AUTOSAR XML (schema 4-2-2)
package /ComponentTypes
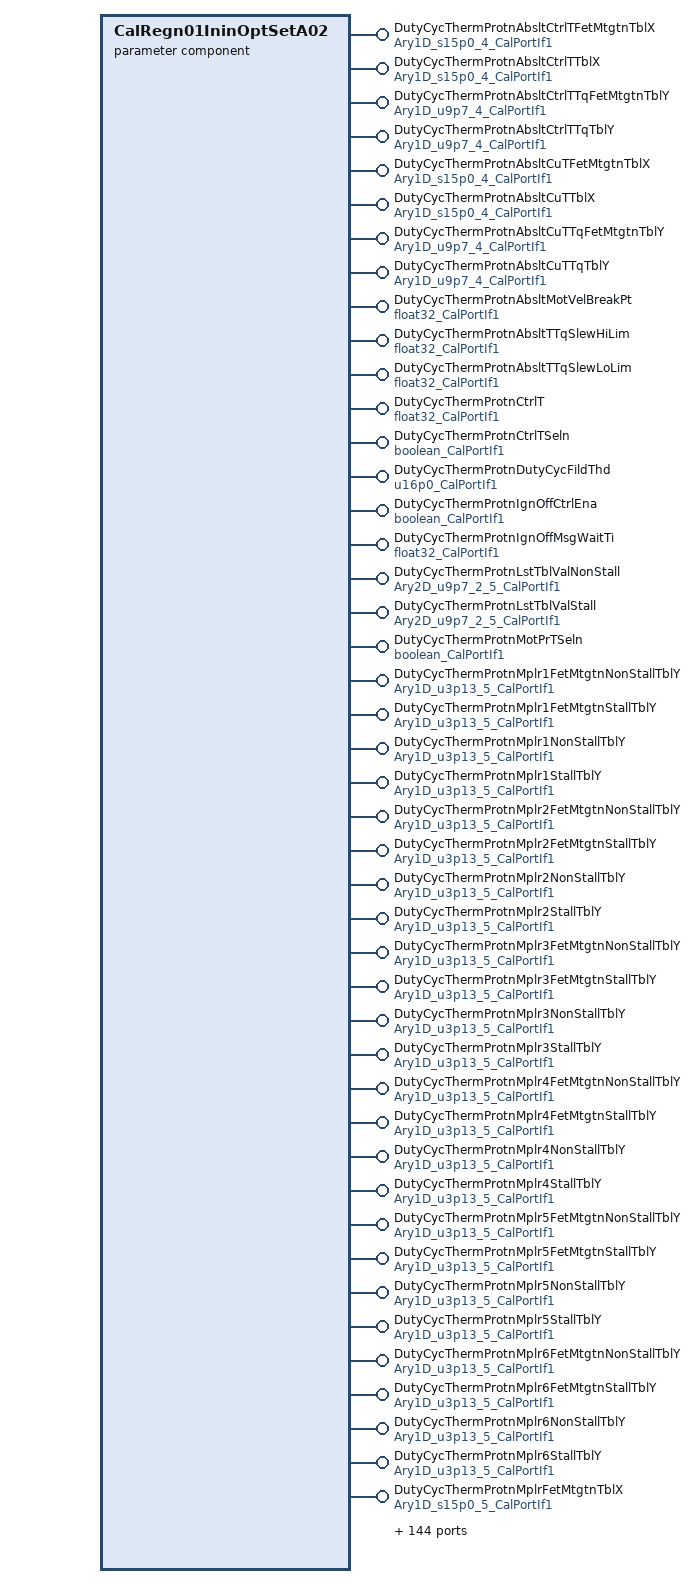
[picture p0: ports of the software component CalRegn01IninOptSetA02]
  parameter sw component type CalRegn01IninOptSetA02
    188 x provide port:
      DutyCycThermProtnAbsltCtrlTFetMtgtnTblX: parameter-provide-com-spec{init-value=[122, 123, 125, 127], parameter=Ary1D}, provided-interface=Ary1D_s15p0_4_CalPortIf1
      DutyCycThermProtnAbsltCtrlTTblX: parameter-provide-com-spec{init-value=[122, 123, 125, 127], parameter=Ary1D}, provided-interface=Ary1D_s15p0_4_CalPortIf1
      DutyCycThermProtnAbsltCtrlTTqFetMtgtnTblY: parameter-provide-com-spec{init-value=[346, 287, 234, 0], parameter=Ary1D}, provided-interface=Ary1D_u9p7_4_CalPortIf1
      DutyCycThermProtnAbsltCtrlTTqTblY: parameter-provide-com-spec{init-value=[346, 287, 234, 0], parameter=Ary1D}, provided-interface=Ary1D_u9p7_4_CalPortIf1
      DutyCycThermProtnAbsltCuTFetMtgtnTblX: parameter-provide-com-spec{init-value=[122, 123, 125, 127], parameter=Ary1D}, provided-interface=Ary1D_s15p0_4_CalPortIf1
      DutyCycThermProtnAbsltCuTTblX: parameter-provide-com-spec{init-value=[122, 123, 125, 127], parameter=Ary1D}, provided-interface=Ary1D_s15p0_4_CalPortIf1
      DutyCycThermProtnAbsltCuTTqFetMtgtnTblY: parameter-provide-com-spec{init-value=[346, 287, 234, 0], parameter=Ary1D}, provided-interface=Ary1D_u9p7_4_CalPortIf1
      DutyCycThermProtnAbsltCuTTqTblY: parameter-provide-com-spec{init-value=[346, 287, 234, 0], parameter=Ary1D}, provided-interface=Ary1D_u9p7_4_CalPortIf1
      DutyCycThermProtnAbsltMotVelBreakPt: parameter-provide-com-spec{init-value=1.375, parameter=Val}, provided-interface=float32_CalPortIf1
      DutyCycThermProtnAbsltTTqSlewHiLim: parameter-provide-com-spec{init-value=0.3, parameter=Val}, provided-interface=float32_CalPortIf1
      DutyCycThermProtnAbsltTTqSlewLoLim: parameter-provide-com-spec{init-value=0.3, parameter=Val}, provided-interface=float32_CalPortIf1
      DutyCycThermProtnCtrlT: parameter-provide-com-spec{init-value=70, parameter=Val}, provided-interface=float32_CalPortIf1
      DutyCycThermProtnCtrlTSeln: parameter-provide-com-spec{init-value=1, parameter=Logl}, provided-interface=boolean_CalPortIf1
      DutyCycThermProtnDutyCycFildThd: parameter-provide-com-spec{init-value=92, parameter=Val}, provided-interface=u16p0_CalPortIf1
      DutyCycThermProtnIgnOffCtrlEna: parameter-provide-com-spec{init-value=0, parameter=Logl}, provided-interface=boolean_CalPortIf1
      DutyCycThermProtnIgnOffMsgWaitTi: parameter-provide-com-spec{init-value=0.5, parameter=Val}, provided-interface=float32_CalPortIf1
      DutyCycThermProtnLstTblValNonStall: parameter-provide-com-spec{init-value=[[128, 128, 128, 44, 44], [128, 128, 128, 44, 44]], parameter=Ary2D}, provided-interface=Ary2D_u9p7_2_5_CalPortIf1
      DutyCycThermProtnLstTblValStall: parameter-provide-com-spec{init-value=[[124, 124, 124, 40, 40], [124, 124, 124, 40, 40]], parameter=Ary2D}, provided-interface=Ary2D_u9p7_2_5_CalPortIf1
      DutyCycThermProtnMotPrTSeln: parameter-provide-com-spec{init-value=1, parameter=Logl}, provided-interface=boolean_CalPortIf1
      DutyCycThermProtnMplr1FetMtgtnNonStallTblY: parameter-provide-com-spec{init-value=[127, 127, 127, 1630, 1630], parameter=Ary1D}, provided-interface=Ary1D_u3p13_5_CalPortIf1
      DutyCycThermProtnMplr1FetMtgtnStallTblY: parameter-provide-com-spec{init-value=[133, 133, 133, 180, 180], parameter=Ary1D}, provided-interface=Ary1D_u3p13_5_CalPortIf1
      DutyCycThermProtnMplr1NonStallTblY: parameter-provide-com-spec{init-value=[127, 127, 127, 1630, 1630], parameter=Ary1D}, provided-interface=Ary1D_u3p13_5_CalPortIf1
      DutyCycThermProtnMplr1StallTblY: parameter-provide-com-spec{init-value=[133, 133, 133, 180, 180], parameter=Ary1D}, provided-interface=Ary1D_u3p13_5_CalPortIf1
      DutyCycThermProtnMplr2FetMtgtnNonStallTblY: parameter-provide-com-spec{init-value=[159, 159, 159, 281, 281], parameter=Ary1D}, provided-interface=Ary1D_u3p13_5_CalPortIf1
      DutyCycThermProtnMplr2FetMtgtnStallTblY: parameter-provide-com-spec{init-value=[167, 167, 167, 310, 310], parameter=Ary1D}, provided-interface=Ary1D_u3p13_5_CalPortIf1
      DutyCycThermProtnMplr2NonStallTblY: parameter-provide-com-spec{init-value=[159, 159, 159, 281, 281], parameter=Ary1D}, provided-interface=Ary1D_u3p13_5_CalPortIf1
      DutyCycThermProtnMplr2StallTblY: parameter-provide-com-spec{init-value=[167, 167, 167, 310, 310], parameter=Ary1D}, provided-interface=Ary1D_u3p13_5_CalPortIf1
      DutyCycThermProtnMplr3FetMtgtnNonStallTblY: parameter-provide-com-spec{init-value=[199, 199, 199, 1282, 1282], parameter=Ary1D}, provided-interface=Ary1D_u3p13_5_CalPortIf1
      DutyCycThermProtnMplr3FetMtgtnStallTblY: parameter-provide-com-spec{init-value=[210, 210, 210, 1707, 1707], parameter=Ary1D}, provided-interface=Ary1D_u3p13_5_CalPortIf1
      DutyCycThermProtnMplr3NonStallTblY: parameter-provide-com-spec{init-value=[199, 199, 199, 1282, 1282], parameter=Ary1D}, provided-interface=Ary1D_u3p13_5_CalPortIf1
      DutyCycThermProtnMplr3StallTblY: parameter-provide-com-spec{init-value=[210, 210, 210, 1707, 1707], parameter=Ary1D}, provided-interface=Ary1D_u3p13_5_CalPortIf1
      DutyCycThermProtnMplr4FetMtgtnNonStallTblY: parameter-provide-com-spec{init-value=5 x 1, parameter=Ary1D}, provided-interface=Ary1D_u3p13_5_CalPortIf1
      DutyCycThermProtnMplr4FetMtgtnStallTblY: parameter-provide-com-spec{init-value=5 x 1, parameter=Ary1D}, provided-interface=Ary1D_u3p13_5_CalPortIf1
      DutyCycThermProtnMplr4NonStallTblY: parameter-provide-com-spec{init-value=5 x 1, parameter=Ary1D}, provided-interface=Ary1D_u3p13_5_CalPortIf1
      DutyCycThermProtnMplr4StallTblY: parameter-provide-com-spec{init-value=5 x 1, parameter=Ary1D}, provided-interface=Ary1D_u3p13_5_CalPortIf1
      DutyCycThermProtnMplr5FetMtgtnNonStallTblY: parameter-provide-com-spec{init-value=[998, 998, 998, 9535, 9535], parameter=Ary1D}, provided-interface=Ary1D_u3p13_5_CalPortIf1
      DutyCycThermProtnMplr5FetMtgtnStallTblY: parameter-provide-com-spec{init-value=[998, 998, 998, 9535, 9535], parameter=Ary1D}, provided-interface=Ary1D_u3p13_5_CalPortIf1
      DutyCycThermProtnMplr5NonStallTblY: parameter-provide-com-spec{init-value=[998, 998, 998, 9535, 9535], parameter=Ary1D}, provided-interface=Ary1D_u3p13_5_CalPortIf1
      DutyCycThermProtnMplr5StallTblY: parameter-provide-com-spec{init-value=[998, 998, 998, 9535, 9535], parameter=Ary1D}, provided-interface=Ary1D_u3p13_5_CalPortIf1
      DutyCycThermProtnMplr6FetMtgtnNonStallTblY: parameter-provide-com-spec{init-value=5 x 1, parameter=Ary1D}, provided-interface=Ary1D_u3p13_5_CalPortIf1
      DutyCycThermProtnMplr6FetMtgtnStallTblY: parameter-provide-com-spec{init-value=5 x 1, parameter=Ary1D}, provided-interface=Ary1D_u3p13_5_CalPortIf1
      DutyCycThermProtnMplr6NonStallTblY: parameter-provide-com-spec{init-value=5 x 1, parameter=Ary1D}, provided-interface=Ary1D_u3p13_5_CalPortIf1
      DutyCycThermProtnMplr6StallTblY: parameter-provide-com-spec{init-value=5 x 1, parameter=Ary1D}, provided-interface=Ary1D_u3p13_5_CalPortIf1
      DutyCycThermProtnMplrFetMtgtnTblX: parameter-provide-com-spec{init-value=[-40, 0, 83, 84, 85], parameter=Ary1D}, provided-interface=Ary1D_s15p0_5_CalPortIf1
      DutyCycThermProtnMplrTblX: parameter-provide-com-spec{init-value=[-40, 0, 83, 84, 85], parameter=Ary1D}, provided-interface=Ary1D_s15p0_5_CalPortIf1
      DutyCycThermProtnMplrTSeln: parameter-provide-com-spec{init-value=1, parameter=Logl}, provided-interface=boolean_CalPortIf1
      DutyCycThermProtnSlowFilTSeln: parameter-provide-com-spec{init-value=0, parameter=Logl}, provided-interface=boolean_CalPortIf1
      DutyCycThermProtnThermLimScaFac: parameter-provide-com-spec{init-value=0.5, parameter=Val}, provided-interface=float32_CalPortIf1
      DutyCycThermProtnThermLoadLimTblX: parameter-provide-com-spec{init-value=[[0, 76, 80, 84, 88, 92, 96, 100], [0, 76, 80, 84, 88, 92, 96, 100]], parameter=Ary2D}, provided-interface=Ary2D_u16p0_2_8_CalPortIf1
      DutyCycThermProtnThermLoadLimTblY: parameter-provide-com-spec{init-value=[[346, 346, 346, 346, 287, 234, 181, 128], [346, 346, 346, 346, 287, 234, 181, 128]], parameter=Ary2D}, provided-interface=Ary2D_u9p7_2_8_CalPortIf1
      DutyCycThermProtnTqCmdSlewDwn: parameter-provide-com-spec{init-value=0.3, parameter=Val}, provided-interface=float32_CalPortIf1
      DutyCycThermProtnTqCmdSlewUp: parameter-provide-com-spec{init-value=0.3, parameter=Val}, provided-interface=float32_CalPortIf1
      HiLoadStallLimrMotVelMgnThd: parameter-provide-com-spec{init-value=[1.375, 1.375], parameter=Ary1D}, provided-interface=Ary1D_f32_2_CalPortIf1
      HiLoadStallLimrStallMotTqCmdFetMtgtnLimX: parameter-provide-com-spec{init-value=[0, 563, 640, 717, 768, 768], parameter=Ary1D}, provided-interface=Ary1D_u8p8_6_CalPortIf1
      HiLoadStallLimrStallMotTqCmdFetMtgtnLimY: parameter-provide-com-spec{init-value=[768, 768, 512, 256, 0, 0], parameter=Ary1D}, provided-interface=Ary1D_u8p8_6_CalPortIf1
      HiLoadStallLimrStallMotTqCmdLimX: parameter-provide-com-spec{init-value=[0, 563, 640, 717, 768, 768], parameter=Ary1D}, provided-interface=Ary1D_u8p8_6_CalPortIf1
      HiLoadStallLimrStallMotTqCmdLimY: parameter-provide-com-spec{init-value=[768, 768, 512, 256, 0, 0], parameter=Ary1D}, provided-interface=Ary1D_u8p8_6_CalPortIf1
      HiLoadStallLimrStallMotTqLimSlewRate: parameter-provide-com-spec{init-value=[0.101563, 0.101563], parameter=Ary1D}, provided-interface=Ary1D_f32_2_CalPortIf1
      HiLoadStallLimrStallThermLimSca: parameter-provide-com-spec{init-value=0.5, parameter=Val}, provided-interface=float32_CalPortIf1
      LrndRackCentrMotTqThd: parameter-provide-com-spec{init-value=2.8, parameter=Val}, provided-interface=float32_CalPortIf1
      LrndRackCentrMotVelThd: parameter-provide-com-spec{init-value=25, parameter=Val}, provided-interface=float32_CalPortIf1
      MotCtrlPrmEstimnFetRNom: parameter-provide-com-spec{init-value=0.0052, parameter=Val}, provided-interface=float32_CalPortIf1
      MotCtrlPrmEstimnMotBackEmfConHiLim: parameter-provide-com-spec{init-value=0.045, parameter=Val}, provided-interface=float32_CalPortIf1
      MotCtrlPrmEstimnMotBackEmfConLoLim: parameter-provide-com-spec{init-value=0.031, parameter=Val}, provided-interface=float32_CalPortIf1
      MotCtrlPrmEstimnMotBackEmfConNom: parameter-provide-com-spec{init-value=0.04, parameter=Val}, provided-interface=float32_CalPortIf1
      MotCtrlPrmEstimnMotBackEmfConSatnScaIvtrLoaMtgtn: parameter-provide-com-spec{init-value=1, parameter=Val}, provided-interface=float32_CalPortIf1
      MotCtrlPrmEstimnMotBackEmfConSatnX: parameter-provide-com-spec{init-value=[0, 1280, 2560, 3840, 5120, 6400, 7680, 8960, 10240, 11520, 12800, 14080, 15360, 16640, 19200, 21760], parameter=Ary1D}, provided-interface=Ary1D_u9p7_16_CalPortIf1
      MotCtrlPrmEstimnMotBackEmfConSatnY: parameter-provide-com-spec{init-value=[16384, 16384, 16384, 16384, 16384, 16384, 16384, 16384, 16384, 16384, 16384, 16370, 16336, 16276, 16095, 15869], parameter=Ary1D}, provided-interface=Ary1D_u2p14_16_CalPortIf1
      MotCtrlPrmEstimnMotCurrDaxInduSatnBilnrSeln: parameter-provide-com-spec{init-value=[0, 3200, 6400, 9600, 12800, 16000], parameter=Ary1D}, provided-interface=Ary1D_u9p7_6_CalPortIf1
      MotCtrlPrmEstimnMotCurrQaxInduSatnX: parameter-provide-com-spec{init-value=[0, 3200, 6400, 9600, 12800, 16000, 19200], parameter=Ary1D}, provided-interface=Ary1D_u9p7_7_CalPortIf1
      MotCtrlPrmEstimnMotInduDaxHiLim: parameter-provide-com-spec{init-value=0.00013, parameter=Val}, provided-interface=float32_CalPortIf1
      MotCtrlPrmEstimnMotInduDaxIvtrLoaMtgtn: parameter-provide-com-spec{init-value=0.00013, parameter=Val}, provided-interface=float32_CalPortIf1
      MotCtrlPrmEstimnMotInduDaxLoLim: parameter-provide-com-spec{init-value=0.0001, parameter=Val}, provided-interface=float32_CalPortIf1
      MotCtrlPrmEstimnMotInduDaxNom: parameter-provide-com-spec{init-value=0.00011889, parameter=Val}, provided-interface=float32_CalPortIf1
      MotCtrlPrmEstimnMotInduDaxSatnScaY: parameter-provide-com-spec{init-value=6 x [16384, 16384, 16384, 16384, 16384, 16305, 16096], parameter=Ary2D}, provided-interface=Ary2D_u2p14_6_7_CalPortIf1
      MotCtrlPrmEstimnMotInduQaxHiLim: parameter-provide-com-spec{init-value=0.00013, parameter=Val}, provided-interface=float32_CalPortIf1
      MotCtrlPrmEstimnMotInduQaxIvtrLoaMtgtn: parameter-provide-com-spec{init-value=0.00013, parameter=Val}, provided-interface=float32_CalPortIf1
      MotCtrlPrmEstimnMotInduQaxLoLim: parameter-provide-com-spec{init-value=0.0001, parameter=Val}, provided-interface=float32_CalPortIf1
      MotCtrlPrmEstimnMotInduQaxNom: parameter-provide-com-spec{init-value=0.00011889, parameter=Val}, provided-interface=float32_CalPortIf1
      MotCtrlPrmEstimnMotInduQaxSatnScaY: parameter-provide-com-spec{init-value=6 x [16384, 16384, 16384, 16384, 16384, 16305, 16096], parameter=Ary2D}, provided-interface=Ary2D_u2p14_6_7_CalPortIf1
      MotCtrlPrmEstimnMotRHiLim: parameter-provide-com-spec{init-value=0.032, parameter=Val}, provided-interface=float32_CalPortIf1
      MotCtrlPrmEstimnMotRLoLim: parameter-provide-com-spec{init-value=0.01246, parameter=Val}, provided-interface=float32_CalPortIf1
      MotCtrlPrmEstimnMotRNom: parameter-provide-com-spec{init-value=0.0139, parameter=Val}, provided-interface=float32_CalPortIf1
      MotCtrlPrmEstimnMotWidgThermCoeff: parameter-provide-com-spec{init-value=0.0039, parameter=Val}, provided-interface=float32_CalPortIf1
      MotCtrlPrmEstimnTNom: parameter-provide-com-spec{init-value=25, parameter=Val}, provided-interface=float32_CalPortIf1
      MotCurrPeakEstimnCurrFilFrq: parameter-provide-com-spec{init-value=8, parameter=Val}, provided-interface=float32_CalPortIf1
      MotCurrPeakEstimnCurrPeakEstimdFilFrq: parameter-provide-com-spec{init-value=0.03, parameter=Val}, provided-interface=float32_CalPortIf1
      MotCurrRegCfgMotClsdLoopBwDaxY: parameter-provide-com-spec{init-value=[12800, 19200, 19200, 19200], parameter=Ary1D}, provided-interface=Ary1D_u10p6_4_CalPortIf1
      MotCurrRegCfgMotClsdLoopBwQaxY: parameter-provide-com-spec{init-value=[12800, 19200, 19200, 19200], parameter=Ary1D}, provided-interface=Ary1D_u10p6_4_CalPortIf1
      MotCurrRegCfgMotDampgRatDax: parameter-provide-com-spec{init-value=1, parameter=Val}, provided-interface=float32_CalPortIf1
      MotCurrRegCfgMotDampgRatQax: parameter-provide-com-spec{init-value=1, parameter=Val}, provided-interface=float32_CalPortIf1
      MotCurrRegCfgMotNatFrqDaxY: parameter-provide-com-spec{init-value=[38400, 38400, 38400, 38400], parameter=Ary1D}, provided-interface=Ary1D_u9p7_4_CalPortIf1
      MotCurrRegCfgMotNatFrqQaxY: parameter-provide-com-spec{init-value=[38400, 38400, 38400, 38400], parameter=Ary1D}, provided-interface=Ary1D_u9p7_4_CalPortIf1
      MotCurrRegCfgMotRVirtDax: parameter-provide-com-spec{init-value=0, parameter=Val}, provided-interface=float32_CalPortIf1
      MotCurrRegCfgMotRVirtQax: parameter-provide-com-spec{init-value=0, parameter=Val}, provided-interface=float32_CalPortIf1
      MotCurrRegCfgMotVelFilFrq: parameter-provide-com-spec{init-value=10, parameter=Val}, provided-interface=float32_CalPortIf1
      MotCurrRegVltgLimrCurrLoaScarSlewRate: parameter-provide-com-spec{init-value=100, parameter=Val}, provided-interface=float32_CalPortIf1
      MotCurrRegVltgLimrDaxAntiWdupCoeff: parameter-provide-com-spec{init-value=0, parameter=Val}, provided-interface=float32_CalPortIf1
      MotCurrRegVltgLimrDualEcuLoaScarSlewRate: parameter-provide-com-spec{init-value=100, parameter=Val}, provided-interface=float32_CalPortIf1
      MotCurrRegVltgLimrFETLoaScarSlewRate: parameter-provide-com-spec{init-value=100, parameter=Val}, provided-interface=float32_CalPortIf1
      MotCurrRegVltgLimrIvtrLoaScarSlewRate: parameter-provide-com-spec{init-value=100, parameter=Val}, provided-interface=float32_CalPortIf1
      MotCurrRegVltgLimrMotVltgBrdgLpFilFrq: parameter-provide-com-spec{init-value=200, parameter=Val}, provided-interface=float32_CalPortIf1
      MotCurrRegVltgLimrMotVltgDaxIntglHiLim: parameter-provide-com-spec{init-value=9, parameter=Val}, provided-interface=float32_CalPortIf1
      MotCurrRegVltgLimrMotVltgDaxIntglLoLim: parameter-provide-com-spec{init-value=-4.5, parameter=Val}, provided-interface=float32_CalPortIf1
      MotCurrRegVltgLimrMotVltgQaxFfLpFilFrq: parameter-provide-com-spec{init-value=500, parameter=Val}, provided-interface=float32_CalPortIf1
      MotCurrRegVltgLimrMotVltgQaxIntglHiLim: parameter-provide-com-spec{init-value=14.5, parameter=Val}, provided-interface=float32_CalPortIf1
      MotCurrRegVltgLimrMotVltgQaxIntglLoLim: parameter-provide-com-spec{init-value=-14.5, parameter=Val}, provided-interface=float32_CalPortIf1
      MotCurrRegVltgLimrQaxAntiWdupCoeff: parameter-provide-com-spec{init-value=0, parameter=Val}, provided-interface=float32_CalPortIf1
      MotCurrRegVltgLimrQaxAntiWdupScagDi: parameter-provide-com-spec{init-value=0, parameter=Logl}, provided-interface=boolean_CalPortIf1
      MotRefMdlCurrDaxBoostGain: parameter-provide-com-spec{init-value=0, parameter=Val}, provided-interface=float32_CalPortIf1
      MotRefMdlCurrDaxBoostTqScaX: parameter-provide-com-spec{init-value=[0, 6144, 7168, 8192, 9216, 10240, 12288, 14336, 16384, 18432, 20480], parameter=Ary1D}, provided-interface=Ary1D_u4p12_11_CalPortIf1
      MotRefMdlCurrDaxBoostTqScaY: parameter-provide-com-spec{init-value=[0, 16384, 19661, 22938, 23757, 25395, 27034, 27853, 29491, 31130, 32768], parameter=Ary1D}, provided-interface=Ary1D_u1p15_11_CalPortIf1
      MotRefMdlCurrDaxQaxRefDelta: parameter-provide-com-spec{init-value=[-3.1415927, -2.3561945, -1.5707964, -0.7853982, 0, 0.7853982, 1.5707964, 2.3561945], parameter=Ary1D}, provided-interface=Ary1D_f32_8_CalPortIf1
      MotRefMdlCurrItrnTolr: parameter-provide-com-spec{init-value=0.1, parameter=Val}, provided-interface=float32_CalPortIf1
      MotRefMdlMotCurrDaxMaxSca: parameter-provide-com-spec{init-value=1, parameter=Val}, provided-interface=float32_CalPortIf1
      MotRefMdlQuad13VltgSdlX: parameter-provide-com-spec{init-value=[0, 3200, 6400, 9600, 16000, 19200, 22400, 25600, 28800, 35200], parameter=Ary1D}, provided-interface=Ary1D_u11p5_10_CalPortIf1
      MotRefMdlQuad13VltgSdlY: parameter-provide-com-spec{init-value=10 x 0, parameter=Ary1D}, provided-interface=Ary1D_u3p13_10_CalPortIf1
      MotRefMdlQuad24VltgSdlX: parameter-provide-com-spec{init-value=[0, 3200, 6400, 9600, 16000, 19200, 22400, 25600, 28800, 35200], parameter=Ary1D}, provided-interface=Ary1D_u11p5_10_CalPortIf1
      MotRefMdlQuad24VltgSdlY: parameter-provide-com-spec{init-value=10 x 0, parameter=Ary1D}, provided-interface=Ary1D_u3p13_10_CalPortIf1
      MotRefMdlVltgOverRThdSca: parameter-provide-com-spec{init-value=0.25, parameter=Val}, provided-interface=float32_CalPortIf1
      MotTqTranlDampgCmdLim: parameter-provide-com-spec{init-value=3, parameter=Val}, provided-interface=float32_CalPortIf1
      MotTqTranlDampgVelThd: parameter-provide-com-spec{init-value=2.3, parameter=Val}, provided-interface=float32_CalPortIf1
      PwrLimrAssiRednLpFilFrq: parameter-provide-com-spec{init-value=0.365, parameter=Val}, provided-interface=float32_CalPortIf1
      PwrLimrBackEmfConStdT: parameter-provide-com-spec{init-value=0.0335999, parameter=Val}, provided-interface=float32_CalPortIf1
      PwrLimrBrdgVltgAdjSlew: parameter-provide-com-spec{init-value=0.5, parameter=Val}, provided-interface=float32_CalPortIf1
      PwrLimrBrdgVltgAltFltAdj: parameter-provide-com-spec{init-value=1, parameter=Val}, provided-interface=float32_CalPortIf1
      PwrLimrFilAssiRednThd: parameter-provide-com-spec{init-value=0.6, parameter=Val}, provided-interface=float32_CalPortIf1
      PwrLimrLoVoltAssiRcvrThd: parameter-provide-com-spec{init-value=13.5, parameter=Val}, provided-interface=float32_CalPortIf1
      PwrLimrLoVoltAssiRcvrTi: parameter-provide-com-spec{init-value=2000, parameter=Val}, provided-interface=uint16_CalPortIf1
      PwrLimrMotEnvlpX: parameter-provide-com-spec{init-value=[-17600, -12800, -10400, -8800, -5657, -4600, -3499, -1731, 0, 1731, 3499, 4600, 5657, 8800], parameter=Ary1D}, provided-interface=Ary1D_s11p4_14_CalPortIf1
      PwrLimrMotEnvlpY: parameter-provide-com-spec{init-value=[1475, 2867, 3891, 4710, 7168, 8397, 9486, 9486, 9486, 9486, 7277, 5994, 4506, 0], parameter=Ary1D}, provided-interface=Ary1D_u5p11_14_CalPortIf1
      PwrLimrMotVelLpFilFrq: parameter-provide-com-spec{init-value=100, parameter=Val}, provided-interface=float32_CalPortIf1
      PwrLimrSpdAdjSlewDec: parameter-provide-com-spec{init-value=3.125, parameter=Val}, provided-interface=float32_CalPortIf1
      PwrLimrSpdAdjSlewEna: parameter-provide-com-spec{init-value=1, parameter=Logl}, provided-interface=boolean_CalPortIf1
      PwrLimrSpdAdjSlewInc: parameter-provide-com-spec{init-value=3125, parameter=Val}, provided-interface=float32_CalPortIf1
      PwrLimrStdOperMotEnvlpX: parameter-provide-com-spec{init-value=[0, 2182, 5717, 7919, 10034, 16320], parameter=Ary1D}, provided-interface=Ary1D_u11p5_6_CalPortIf1
      PwrLimrStdOperMotEnvlpY: parameter-provide-com-spec{init-value=[18973, 18973, 14553, 11989, 9011, 0], parameter=Ary1D}, provided-interface=Ary1D_u4p12_6_CalPortIf1
      PwrLimrVltgDptMotVelOffsX: parameter-provide-com-spec{init-value=[17496, 18728, 18928, 19136, 19336, 19544, 20568, 21592, 22208, 25280], parameter=Ary1D}, provided-interface=Ary1D_u5p11_10_CalPortIf1
      PwrLimrVltgDptMotVelOffsY: parameter-provide-com-spec{init-value=[3395, 2859, 2769, 2680, 2591, 2501, 2054, 1608, 1340, 0], parameter=Ary1D}, provided-interface=Ary1D_u11p5_10_CalPortIf1
      SysGlbPrmSysTqRat: parameter-provide-com-spec{init-value=20, parameter=Val}, provided-interface=float32_CalPortIf1
      TEstimnAmbPwrMplr: parameter-provide-com-spec{init-value=[0.01, 0.01, 0.01], parameter=Ary1D}, provided-interface=Ary1D_f32_3_CalPortIf1
      TEstimnAmbTSca: parameter-provide-com-spec{init-value=[0.9, 0.9, 0.9], parameter=Ary1D}, provided-interface=Ary1D_f32_3_CalPortIf1
      TEstimnAssiMechAmbLpFilFrq: parameter-provide-com-spec{init-value=0.024, parameter=Val}, provided-interface=float32_CalPortIf1
      TEstimnAssiMechAmbLpFilFrqDualEcuFltMtgtn: parameter-provide-com-spec{init-value=0.024, parameter=Val}, provided-interface=float32_CalPortIf1
      TEstimnAssiMechAmbLpFilFrqFetMtgtnEna: parameter-provide-com-spec{init-value=0.024, parameter=Val}, provided-interface=float32_CalPortIf1
      TEstimnAssiMechAmbMplr: parameter-provide-com-spec{init-value=[0.01, 0.01, 0.01], parameter=Ary1D}, provided-interface=Ary1D_f32_3_CalPortIf1
      TEstimnAssiMechCorrLim: parameter-provide-com-spec{init-value=[60, 60, 60], parameter=Ary1D}, provided-interface=Ary1D_f32_3_CalPortIf1
      TEstimnAssiMechDampgSca: parameter-provide-com-spec{init-value=[0.0001, 0.0001, 0.0001], parameter=Ary1D}, provided-interface=Ary1D_f32_3_CalPortIf1
      TEstimnAssiMechDftT: parameter-provide-com-spec{init-value=[50, 50, 50], parameter=Ary1D}, provided-interface=Ary1D_f32_3_CalPortIf1
      TEstimnAssiMechLLFilCoeffA1: parameter-provide-com-spec{init-value=[0.99996858, 0.99996858, 0.99996858], parameter=Ary1D}, provided-interface=Ary1D_f32_3_CalPortIf1
      TEstimnAssiMechLLFilCoeffB0: parameter-provide-com-spec{init-value=[0.4761987, 0.4761987, 0.4761987], parameter=Ary1D}, provided-interface=Ary1D_f32_3_CalPortIf1
      TEstimnAssiMechLLFilCoeffB1: parameter-provide-com-spec{init-value=[-0.4761673, -0.4761673, -0.4761673], parameter=Ary1D}, provided-interface=Ary1D_f32_3_CalPortIf1
      TEstimnAssiMechSlew: parameter-provide-com-spec{init-value=[1, 1, 1], parameter=Ary1D}, provided-interface=Ary1D_f32_3_CalPortIf1
      TEstimnCorrnTAssiMech: parameter-provide-com-spec{init-value=[0, 0, 0], parameter=Ary1D}, provided-interface=Ary1D_f32_3_CalPortIf1
      TEstimnCorrnTCu: parameter-provide-com-spec{init-value=[0, 0, 0], parameter=Ary1D}, provided-interface=Ary1D_f32_3_CalPortIf1
      TEstimnCorrnTMag: parameter-provide-com-spec{init-value=[0, 0, 0], parameter=Ary1D}, provided-interface=Ary1D_f32_3_CalPortIf1
      TEstimnCorrnTSi: parameter-provide-com-spec{init-value=[0, 0, 0], parameter=Ary1D}, provided-interface=Ary1D_f32_3_CalPortIf1
      TEstimnCuAmbLpFilFrq: parameter-provide-com-spec{init-value=0.024, parameter=Val}, provided-interface=float32_CalPortIf1
      TEstimnCuAmbLpFilFrqDualEcuFltMtgtn: parameter-provide-com-spec{init-value=0.024, parameter=Val}, provided-interface=float32_CalPortIf1
      TEstimnCuAmbLpFilFrqFetMtgtnEna: parameter-provide-com-spec{init-value=0.024, parameter=Val}, provided-interface=float32_CalPortIf1
      TEstimnCuAmbMplr: parameter-provide-com-spec{init-value=[0.75, 0.75, 0.75], parameter=Ary1D}, provided-interface=Ary1D_f32_3_CalPortIf1
      TEstimnCuCorrnLim: parameter-provide-com-spec{init-value=[80, 80, 80], parameter=Ary1D}, provided-interface=Ary1D_f32_3_CalPortIf1
      TEstimnCuLLFilCoeffA1: parameter-provide-com-spec{init-value=[0.999943, 0.999943, 0.999943], parameter=Ary1D}, provided-interface=Ary1D_f32_3_CalPortIf1
      TEstimnCuLLFilCoeffB0: parameter-provide-com-spec{init-value=[0.86667, 0.86667, 0.86667], parameter=Ary1D}, provided-interface=Ary1D_f32_3_CalPortIf1
      TEstimnCuLLFilCoeffB1: parameter-provide-com-spec{init-value=[-0.866613, -0.866613, -0.866613], parameter=Ary1D}, provided-interface=Ary1D_f32_3_CalPortIf1
      TEstimnEngTSca: parameter-provide-com-spec{init-value=[0.1, 0.1, 0.1], parameter=Ary1D}, provided-interface=Ary1D_f32_3_CalPortIf1
      TEstimnMagAmbLpFilFrq: parameter-provide-com-spec{init-value=0.024, parameter=Val}, provided-interface=float32_CalPortIf1
      TEstimnMagAmbLpFilFrqDualEcuFltMtgtn: parameter-provide-com-spec{init-value=0.024, parameter=Val}, provided-interface=float32_CalPortIf1
      TEstimnMagAmbLpFilFrqFetMtgtnEna: parameter-provide-com-spec{init-value=0.024, parameter=Val}, provided-interface=float32_CalPortIf1
      TEstimnMagAmbMplr: parameter-provide-com-spec{init-value=[0.01, 0.01, 0.01], parameter=Ary1D}, provided-interface=Ary1D_f32_3_CalPortIf1
      TEstimnMagCorrnLim: parameter-provide-com-spec{init-value=[60, 60, 60], parameter=Ary1D}, provided-interface=Ary1D_f32_3_CalPortIf1
      TEstimnMagLLFilCoeffA1: parameter-provide-com-spec{init-value=[0.999962, 0.999962, 0.999962], parameter=Ary1D}, provided-interface=Ary1D_f32_3_CalPortIf1
      TEstimnMagLLFilCoeffB0: parameter-provide-com-spec{init-value=[0.571437, 0.571437, 0.571437], parameter=Ary1D}, provided-interface=Ary1D_f32_3_CalPortIf1
      TEstimnMagLLFilCoeffB1: parameter-provide-com-spec{init-value=[-0.571399, -0.571399, -0.571399], parameter=Ary1D}, provided-interface=Ary1D_f32_3_CalPortIf1
      TEstimnSiAmbLpFilFrq: parameter-provide-com-spec{init-value=0.024, parameter=Val}, provided-interface=float32_CalPortIf1
      TEstimnSiAmbLpFilFrqDualEcuFltMtgtn: parameter-provide-com-spec{init-value=0.024, parameter=Val}, provided-interface=float32_CalPortIf1
      TEstimnSiAmbLpFilFrqFetMtgtnEna: parameter-provide-com-spec{init-value=0.024, parameter=Val}, provided-interface=float32_CalPortIf1
      TEstimnSiAmbMplr: parameter-provide-com-spec{init-value=[0, 0, 0], parameter=Ary1D}, provided-interface=Ary1D_f32_3_CalPortIf1
      TEstimnSiCorrnLim: parameter-provide-com-spec{init-value=[60, 60, 60], parameter=Ary1D}, provided-interface=Ary1D_f32_3_CalPortIf1
      TEstimnSiLLFilCoeffA1: parameter-provide-com-spec{init-value=[0.999889, 0.999889, 0.999889], parameter=Ary1D}, provided-interface=Ary1D_f32_3_CalPortIf1
      TEstimnSiLLFilCoeffB0: parameter-provide-com-spec{init-value=[1.68568, 1.68568, 1.68568], parameter=Ary1D}, provided-interface=Ary1D_f32_3_CalPortIf1
      TEstimnSiLLFilCoeffB1: parameter-provide-com-spec{init-value=[-1.68556, -1.68556, -1.68556], parameter=Ary1D}, provided-interface=Ary1D_f32_3_CalPortIf1
      TEstimnTauAssiMech: parameter-provide-com-spec{init-value=[4000, 4000, 4000], parameter=Ary1D}, provided-interface=Ary1D_f32_3_CalPortIf1
      TEstimnTauCu: parameter-provide-com-spec{init-value=[79, 79, 79], parameter=Ary1D}, provided-interface=Ary1D_f32_3_CalPortIf1
      TEstimnTauMag: parameter-provide-com-spec{init-value=[50, 50, 50], parameter=Ary1D}, provided-interface=Ary1D_f32_3_CalPortIf1
      TEstimnTauSi: parameter-provide-com-spec{init-value=[214, 214, 214], parameter=Ary1D}, provided-interface=Ary1D_f32_3_CalPortIf1
      TEstimnWghtAvrgTDi: parameter-provide-com-spec{init-value=[0, 0, 0], parameter=Ary1D}, provided-interface=Ary1D_logl_3_CalPortIf1
      VehSpdLimrPosMaxOffs2: parameter-provide-com-spec{init-value=120, parameter=Val}, provided-interface=float32_CalPortIf1
